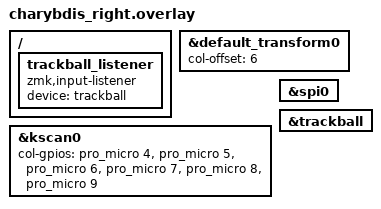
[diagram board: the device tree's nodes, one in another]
/*
 * Copyright (c) 2020 Ryan Cross
 *
 * SPDX-License-Identifier: MIT
 */

#include "charybdis.dtsi"
#include "pmw3610.dtsi"

&default_transform0 {
    col-offset = <6>;
};

&kscan0 {
    col-gpios
        = <&pro_micro 4 GPIO_ACTIVE_HIGH>
        , <&pro_micro 5 GPIO_ACTIVE_HIGH>
        , <&pro_micro 6 GPIO_ACTIVE_HIGH>
        , <&pro_micro 7 GPIO_ACTIVE_HIGH>
        , <&pro_micro 8 GPIO_ACTIVE_HIGH>
        , <&pro_micro 9 GPIO_ACTIVE_HIGH>
        ;
};

&spi0 {
    status = "okay";
};

&trackball {
    status = "okay";
};

// https://github.com/badjeff/zmk-pmw3610-driver
/ {
  trackball_listener {
    compatible = "zmk,input-listener";
    device = <&trackball>;
  };
};
